VERSION ""

NS_ :

BS_:

BU_: Vector__XXX

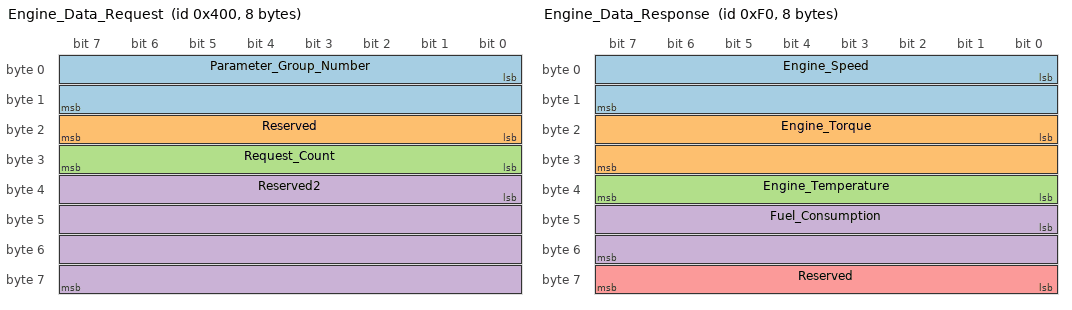
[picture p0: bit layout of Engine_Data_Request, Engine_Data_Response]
BO_ 1024 Engine_Data_Request: 8 Vector__XXX
 SG_ Parameter_Group_Number : 0|16@1+ (1,0) [0|65535] "" Vector__XXX
 SG_ Reserved : 16|8@1+ (1,0) [0|255] "" Vector__XXX
 SG_ Request_Count : 24|8@1+ (1,0) [0|255] "" Vector__XXX
 SG_ Reserved2 : 32|32@1+ (1,0) [0|4294967295] "" Vector__XXX

BO_ 240 Engine_Data_Response: 8 Vector__XXX
 SG_ Engine_Speed : 0|16@1+ (0.125,0) [0|8031.875] "rpm" Vector__XXX
 SG_ Engine_Torque : 16|16@1+ (0.125,-125) [-125|125] "%" Vector__XXX
 SG_ Engine_Temperature : 32|8@1+ (1,0) [0|255] "°C" Vector__XXX
 SG_ Fuel_Consumption : 40|16@1+ (0.05,0) [0|3276.75] "L/h" Vector__XXX
 SG_ Reserved : 56|8@1+ (1,0) [0|255] "" Vector__XXX

CM_ BO_ 1024 "Engine Data Request - PGN 0xCF00400";
CM_ BO_ 240 "Engine Data Response - PGN 0x18FEF100";

BA_DEF_ BO_ "GenMsgCycleTime" INT 0 65535;
BA_DEF_DEF_ "GenMsgCycleTime" 0;
BA_ "GenMsgCycleTime" BO_ 1024 1000;
BA_ "GenMsgCycleTime" BO_ 240 100;
